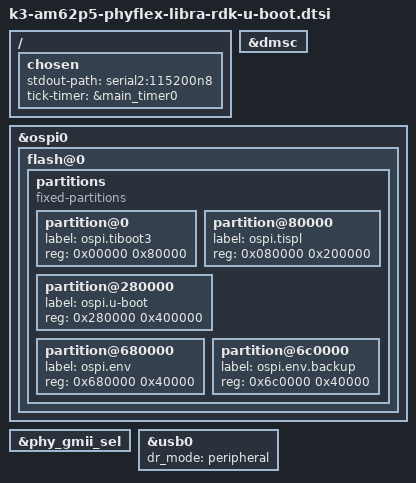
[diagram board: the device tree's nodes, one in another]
// SPDX-License-Identifier: GPL-2.0-only OR MIT
/*
 * Common AM62Px phyBOARD-Lynx dts file for SPLs
 * Copyright (C) 2026 PHYTEC America LLC - https://www.phytec.com/
 */

#include "k3-am62p-phyflex-fpsc-g-binman.dtsi"

/ {
	chosen {
		stdout-path = "serial2:115200n8";
		tick-timer = &main_timer0;
	};
};

&dmsc {
	bootph-pre-ram;
};

&ospi0 {
	flash@0 {
		partitions {
			compatible = "fixed-partitions";
			#address-cells = <1>;
			#size-cells = <1>;

			partition@0 {
				label = "ospi.tiboot3";
				reg = <0x00000 0x80000>;
			};
			partition@80000 {
				label = "ospi.tispl";
				reg = <0x080000 0x200000>;
			};
			partition@280000 {
				label = "ospi.u-boot";
				reg = <0x280000 0x400000>;
			};
			partition@680000 {
				label = "ospi.env";
				reg = <0x680000 0x40000>;
			};
			partition@6c0000 {
				label = "ospi.env.backup";
				reg = <0x6c0000 0x40000>;
			};
		};
	};
};

&phy_gmii_sel {
	bootph-all;
};

/* Required for USB DFU Boot */
&usb0 {
	/* Enable peripheral mode only during bootup
	 * to support DFU while allowing Linux to stay
	 * in OTG mode
	 */
	dr_mode = "peripheral";
};
